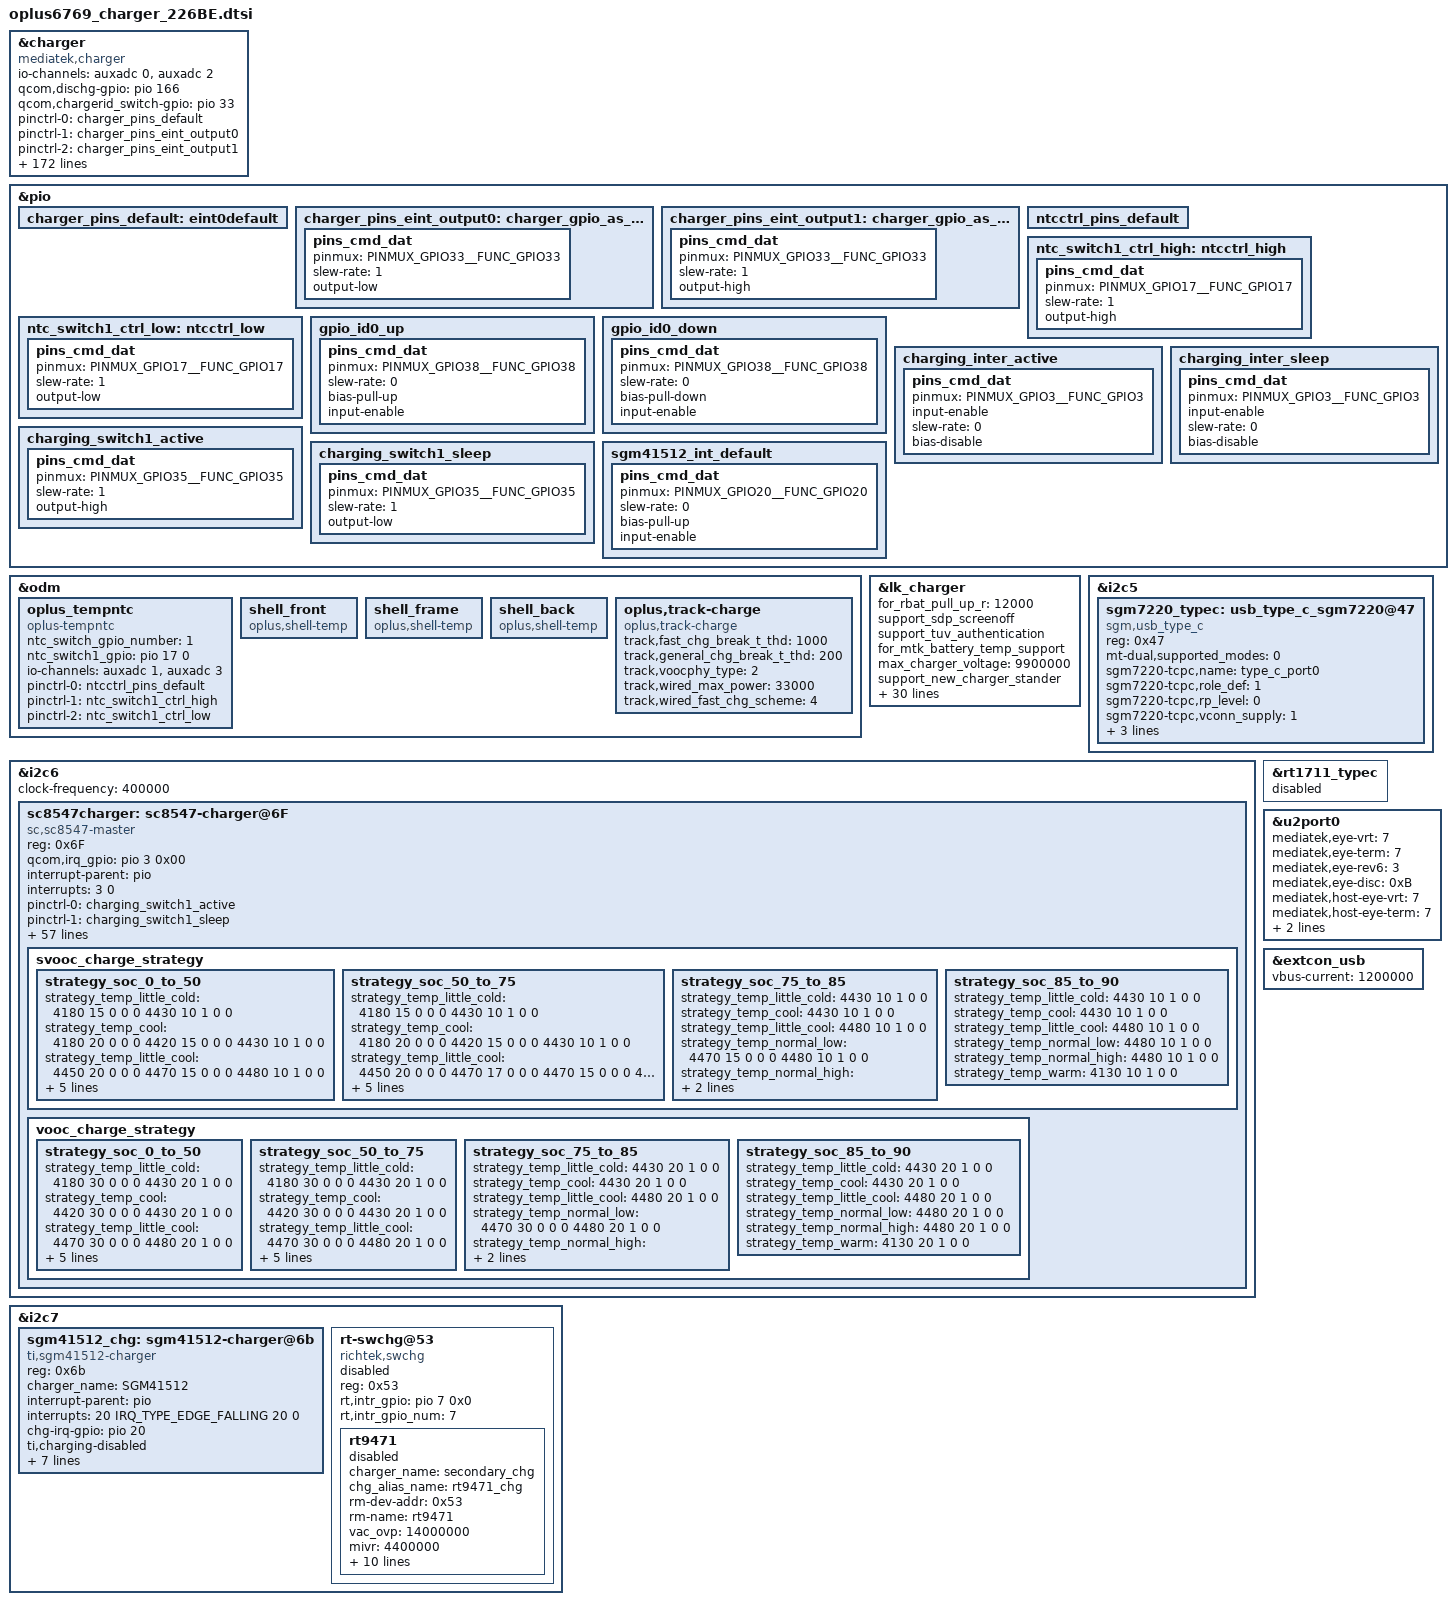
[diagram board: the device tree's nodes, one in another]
// SPDX-License-Identifier: GPL-2.0-only
/*
* Copyright (C) 2020-2021 Oplus. All rights reserved.
*/

//#ifdef OPLUS_CHARGER_BASIC
/*
 * Add for charger bringup
 *
 * CPU:MT6765
 * IRQB
 * CHG_INT(cp irq)                --> GPIO3
 * CC_INTB(cc login irq)          --> GPIO17
 * EINT_CHG_M(main irq)           --> GPIO90
 *
 * GPIO
 * MAIN/CCLOGIN_SCL               --> GPIO48(SCL5)
 * MAIN/CCLOGIN_SDA               --> GPIO49(SDA5)
 * SW_CTRL(uart/vooc switch)      --> GPIO97
 * DISCHARGE_EN(防烧口)           --> GPIO153
 * CHARGER_PUMP_SCL               --> GPIO161(SCL6)
 * CHARGER_PUMP_SDA               --> GPIO162(SDA6)
 * USB_ON(usb/uart&vooc switch)   --> GPIO177
 *
 * AUXADC:
 * 0				-->
 * 1				-->
 * 2				--> USB_TEM_ADC_2
 * 3				-->
 * 4				--> USB_TEM_ADC_1
 * 5				-->
 * 6				-->
 * 7				-->
 * 8				-->
 */
&charger {
	compatible = "mediatek,charger";
	//chgntc_gpio = <&pio 154 0>;

	io-channels = <&auxadc 0>, <&auxadc 2>;
	io-channel-names = "usbtemp-ch3", "usbtemp-ch4";

	qcom,dischg-gpio = <&pio 166 0x00>;
	qcom,chargerid_switch-gpio = <&pio 33 0x00>;
	pinctrl-names = "default", "charger_gpio_as_output_low","charger_gpio_as_output_high", "dischg_disable", "dischg_enable";
	pinctrl-0 = <&charger_pins_default>;
	pinctrl-1 = <&charger_pins_eint_output0>;
	pinctrl-2 = <&charger_pins_eint_output1>;
	pinctrl-3 = <&mtk_pins_usb_burn_en0>;
	pinctrl-4 = <&mtk_pins_usb_burn_en1>;
	//pinctrl-3 = <&ship_sleep_gpio>;
	//pinctrl-4 = <&ship_active_gpio>;
	//pinctrl-5 = <&shortc_active_gpio>;

	chg_battery_id;

	qcom,input_current_charger_ma = <2000>;
	qcom,pd_input_current_charger_ma = <1500>;
	qcom,qc_input_current_charger_ma = <2000>;
	qcom,input_current_usb_ma = <500>;
	qcom,input_current_cdp_ma = <1500>;
	qcom,input_current_camera_ma = <1200>;
	qcom,input_current_calling_ma = <1500>;

	qcom,led_warm_bat_decidegc = <350>;
	qcom,led_high_bat_decidegc = <370>;
	qcom,input_current_led_ma = <1200>;
	qcom,input_current_led_ma_high = <1200>;
	qcom,input_current_led_ma_warm = <1500>;
	qcom,input_current_led_ma_normal = <2000>;

	qcom,vooc_temp_bat_normal_decidegc = <350>;
	qcom,vooc_temp_bat_warm_decidegc = <370>;
	qcom,vooc_temp_bat_hot_decidegc = <440>;
	qcom,input_current_vooc_led_ma_high = <1200>;
	qcom,input_current_vooc_led_ma_warm = <1800>;
	qcom,input_current_vooc_led_ma_normal = <3600>;
	qcom,input_current_vooc_ma_normal = <3600>;

	qcom,input_current_vooc_ma_warm = <3200>;

	qcom,input_current_vooc_ma_high = <2200>;

	qcom,charger_current_vooc_ma_normal = <1800>;

	qcom,iterm_disabled = <0>;
	qcom,iterm_ma = <254>;
	qcom,recharge-mv = <100>;
	qcom,batt_capacity_mah = <5000>;/*typical capacity*/

	qcom,removed_bat_decidegc = <190>;  /*<-19C*/

	qcom,cold_bat_decidegc = <100>;  /*-10C~0C*/
	qcom,temp_cold_vfloat_mv = <4435>;
	qcom,temp_cold_fastchg_current_ma = <600>;
	qcom,temp_cold_fastchg_current_ma_high = <960>;
	qcom,temp_cold_fastchg_current_ma_low = <720>;
	qcom,pd_temp_cold_fastchg_current_ma_high = <800>;
	qcom,pd_temp_cold_fastchg_current_ma_low = <600>;
	qcom,qc_temp_cold_fastchg_current_ma_high = <800>;
	qcom,qc_temp_cold_fastchg_current_ma_low = <600>;

	qcom,little_cold_bat_decidegc = <0>;    /*0C~5C*/
	qcom,temp_little_cold_vfloat_mv = <4435>;
	qcom,temp_little_cold_fastchg_current_ma_high = <2200>;
	qcom,temp_little_cold_fastchg_current_ma_low = <2000>;
	qcom,temp_little_cold_fastchg_current_ma = <2000>;
	qcom,pd_temp_little_cold_fastchg_current_ma_high = <3000>;
	qcom,pd_temp_little_cold_fastchg_current_ma_low = <2000>;
	qcom,qc_temp_little_cold_fastchg_current_ma_high = <3000>;
	qcom,qc_temp_little_cold_fastchg_current_ma_low = <2000>;

	qcom,cool_bat_decidegc = <50>;  /*5C~12C*/
	qcom,temp_cool_vfloat_mv = <4435>;
	qcom,temp_cool_fastchg_current_ma_high = <2200>;
	qcom,temp_cool_fastchg_current_ma_low = <2200>;
	qcom,pd_temp_cool_fastchg_current_ma_high = <3000>;
	qcom,pd_temp_cool_fastchg_current_ma_low = <3000>;
	qcom,qc_temp_cool_fastchg_current_ma_high = <3000>;
	qcom,qc_temp_cool_fastchg_current_ma_low = <3000>;

	qcom,little_cool_bat_decidegc = <120>;  /*12C~16C*/
	qcom,temp_little_cool_vfloat_mv = <4435>;
	qcom,temp_little_cool_fastchg_current_ma = <2200>;
	qcom,pd_temp_little_cool_fastchg_current_ma = <3000>;
	qcom,qc_temp_little_cool_fastchg_current_ma = <3000>;

	qcom,normal_bat_decidegc = <160>;       /*16C~45C*/
	qcom,temp_normal_vfloat_mv = <4435>;
	qcom,temp_normal_fastchg_current_ma = <2200>;
	qcom,pd_temp_normal_fastchg_current_ma = <3000>;
	qcom,qc_temp_normal_fastchg_current_ma = <3000>;

	qcom,warm_bat_decidegc = <450>;         /*45C~53C*/ /*8pin Bat Vooc project need add 3 degree C*/
	qcom,temp_warm_vfloat_mv = <4130>;
	qcom,temp_warm_fastchg_current_ma = <2200>;
	qcom,pd_temp_warm_fastchg_current_ma = <2200>;
	qcom,qc_temp_warm_fastchg_current_ma = <2200>;
	qcom,temp_warm_fastchg_current_ma_led_on = <1000>;

	qcom,hot_bat_decidegc = <530>;

	qcom,non_standard_vfloat_mv = <3980>;
	qcom,non_standard_fastchg_current_ma = <500>;

	qcom,short_c_bat_cv_mv = <4330>;
	qcom,short_c_bat_vfloat_mv = <3800>;
	qcom,short_c_bat_fastchg_current_ma = <512>;

	qcom,cold_vfloat_sw_limit = <4385>;
	qcom,little_cold_vfloat_sw_limit = <4385>;
	qcom,cool_vfloat_sw_limit = <4385>;
	qcom,little_cool_vfloat_sw_limit = <4385>;
	qcom,normal_vfloat_sw_limit = <4385>;
	qcom,warm_vfloat_sw_limit = <4080>;
	qcom,non_standard_vfloat_sw_limit = <3930>;
	qcom,short_c_bat_vfloat_sw_limit = <3750>;

	qcom,max_chg_time_sec = <64800>;
	qcom,charger_hv_thr = <10000>;
	qcom,charger_recv_thr = <9800>;
	qcom,charger_lv_thr = <3400>;
	qcom,vbatt_full_thr = <4435>;
	qcom,vbatt_hv_thr = <4600>;

	qcom,vfloat_step_mv = <8>;
	qcom,cold_vfloat_over_sw_limit = <4445>;
	qcom,little_cold_vfloat_over_sw_limit = <4445>;
	qcom,cool_vfloat_over_sw_limit = <4445>;
	qcom,little_cool_vfloat_over_sw_limit = <4445>;
	qcom,normal_vfloat_over_sw_limit = <4445>;
	qcom,warm_vfloat_over_sw_limit = <4140>;
	qcom,non_standard_vfloat_over_sw_limit = <3990>;

	qcom,vbatt_power_off = <3300>;
	qcom,vbatt_soc_1 = <3410>;
	qcom,vooc_project = <5>;
	qcom,vbatt_num = <1>;
	qcom,voocphy_support = <2>;
	qcom,chargerid_support;
	qcom,ffc_support;
	qcom,smart_charging_screenoff;
	qcom,vooc_show_ui_soc_decimal;
	qcom,ui_soc_decimal_speedmin = <20>;//2A
	qcom,check_batt_full_by_sw;
	qcom,chg_ctrl_by_lcd;
	qcom,chg_ctrl_by_camera;
	qcom,chg_ctrl_by_calling;
	voocphy_support_display_vooc;
	qcom,support_ntc_01c_precision;
	qcom,sw_vfloat_over_protect_enable;

	qcom,normal_vterm_hw_inc = <18>;
	qcom,non_normal_vterm_hw_inc = <18>;
	qcom,usbtemp_batttemp_gap = <12>;

	qcom,ff1_normal_fastchg_ma = <1500>;
	qcom,ff1_warm_fastchg_ma = <1500>;

	qcom,ffc2_normal_fastchg_ma = <1300>;/*12C~35c*/
	qcom,ffc2_temp_warm_decidegc = <350>;
	qcom,ffc2_warm_fastchg_ma = <1400>;/*35C~40c*/
	qcom,ffc2_temp_high_decidegc = <400>;
	qcom,ffc2_temp_low_decidegc = <120>;

	qcom,ff1_exit_step_ma = <450>;
	qcom,ff1_warm_exit_step_ma = <350>;
	qcom,ffc2_exit_step_ma = <150>;
	qcom,ffc2_warm_exit_step_ma = <150>;

	qcom,ffc_normal_vfloat_sw_limit = <4475>;
	qcom,ffc_temp_normal_vfloat_mv = <4550>;
	qcom,ffc_normal_vfloat_over_sw_limit = <4550>;
	qcom,ffc_warm_vfloat_sw_limit = <4475>;

	qcom,ffc2_normal_vfloat_sw_limit = <4475>;
	qcom,ffc2_temp_normal_vfloat_mv = <4550>;
	qcom,ffc2_normal_vfloat_over_sw_limit = <4550>;
	qcom,ffc2_warm_vfloat_sw_limit = <4475>;

	qcom,default_iterm_ma = <254>;
	qcom,default_temp_normal_fastchg_current_ma = <2200>;
	qcom,default_normal_vfloat_sw_limit = <4385>;
	qcom,default_temp_normal_vfloat_mv = <4435>;
	qcom,default_normal_vfloat_over_sw_limit = <4445>;

	qcom,default_temp_little_cool_fastchg_current_ma = <2200>;
	qcom,default_little_cool_vfloat_sw_limit = <4385>;
	qcom,default_temp_little_cool_vfloat_mv = <4435>;
	qcom,default_little_cool_vfloat_over_sw_limit = <4445>;

	//for PD9V or QC9V
	qcom,vbatt_pdqc_to_5v_thr = <4500>;
	qcom,vbatt_pdqc_to_9v_thr = <4500>;

	qcom,vooc-max-input-volt-support = <10000>;     //10V
	qcom,vooc-max-input-current-support = <3000>;   //3A
	qcom,disable-ship-mode;
	qcom,pd_not_support = <1>;
	qcom,qc_not_support = <1>;
	qcom,support_3p6_standard;
	qcom,usb_ntc_pullup = <100000>;
	qcom,mastercharger_psy_set;

	status = "okay";
 };

 &pio {
	charger_pins_default: eint0default {
	};

	charger_pins_eint_output0: charger_gpio_as_output_low {
		pins_cmd_dat {
			pinmux = <PINMUX_GPIO33__FUNC_GPIO33>;
			slew-rate = <1>;
			output-low;
		};
	};

	charger_pins_eint_output1: charger_gpio_as_output_high {
		pins_cmd_dat {
			pinmux = <PINMUX_GPIO33__FUNC_GPIO33>;
			slew-rate = <1>;
			output-high;
		};
	};

	ntcctrl_pins_default: ntcctrl_pins_default {
	};

	ntc_switch1_ctrl_high: ntcctrl_high {
		pins_cmd_dat {
			pinmux = <PINMUX_GPIO17__FUNC_GPIO17>;
			slew-rate = <1>;//0:input direction 1:output direction
			output-high;
		};
	};

	ntc_switch1_ctrl_low: ntcctrl_low {
		pins_cmd_dat {
			pinmux = <PINMUX_GPIO17__FUNC_GPIO17>;
			slew-rate = <1>;
			output-low;
		};
	};
 };

&odm {
	oplus_tempntc: oplus_tempntc {
		compatible = "oplus-tempntc";
		ntc_switch_gpio_number = <1>;
		ntc_switch1_gpio = <&pio 17 0>;
		io-channels = <&auxadc 1>,
				<&auxadc 3>;
		io-channel-names = "auxadc1-flash_or_pa_v",
					"auxadc3-bat_id_or_charge_v";
		pinctrl-names = "default",
			"ntc_switch1_ctrl_high",
			"ntc_switch1_ctrl_low";
		pinctrl-0 = <&ntcctrl_pins_default>;
		pinctrl-1 = <&ntc_switch1_ctrl_high>;
		pinctrl-2 = <&ntc_switch1_ctrl_low>;
		status = "okay";
	};
	shell_front {
 			compatible = "oplus,shell-temp";
 	};

 	shell_frame {
 			compatible = "oplus,shell-temp";
 	};

 	shell_back {
 			compatible = "oplus,shell-temp";
 	};
	oplus,track-charge {
		compatible = "oplus,track-charge";
		track,fast_chg_break_t_thd = <1000>;
		track,general_chg_break_t_thd = <200>;
		track,voocphy_type = <2>;
		track,wired_max_power = <33000>;
		track,wired_fast_chg_scheme = <4>;
	};
};

/* Modify lk charge config */
&lk_charger{
	for_rbat_pull_up_r = <12000>;
	support_sdp_screenoff;
	support_tuv_authentication;
	for_mtk_battery_temp_support;
	max_charger_voltage = <9900000>;
	support_new_charger_stander;
	usb_charger_current = <500000>;
	ac_charger_input_current = <2000000>;
	non_std_ac_charger_current = <2000000>;
	charging_host_charger_current = <1500000>;
	precharge_1_step_current = <350>;

	cold_bat_decidegc = <10>;  /*-10C~0C*/
	dcp_temp_cold_fastchg_current = <300>;
	usb_temp_cold_fastchg_current = <300>;
	cdp_temp_cold_fastchg_current = <300>;

	little_cold_bat_decidegc = <0>;    /*0C~5C*/
	dcp_temp_little_cold_fastchg_current = <800>;
	usb_temp_little_cold_fastchg_current = <500>;
	cdp_temp_little_cold_fastchg_current = <800>;

	cool_bat_decidegc = <5>;  /*5C~12C*/
	dcp_temp_cool_fastchg_current = <1600>;
	usb_temp_cool_fastchg_current = <600>;
	cdp_temp_cool_fastchg_current = <1600>;

	little_cool_bat_decidegc = <12>;  /*12C~16C*/
	dcp_temp_little_cool_fastchg_current = <1600>;
	usb_temp_little_cool_fastchg_current = <600>;
	cdp_temp_little_cool_fastchg_current = <1600>;

	normal_bat_decidegc = <16>;       /*16C~45C*/
	dcp_temp_normal_fastchg_current = <2200>;
	usb_temp_normal_fastchg_current = <600>;
	cdp_temp_normal_fastchg_current = <1600>;

	warm_bat_decidegc = <45>;    /*45C~53C*/
	dcp_temp_warm_fastchg_current = <2200>;
	usb_temp_warm_fastchg_current = <600>;
	cdp_temp_warm_fastchg_current = <2200>;

	hot_bat_decidegc = <53>;
};

&i2c5 {
	sgm7220_typec: usb_type_c_sgm7220@47 {
		compatible = "sgm,usb_type_c"; //
		reg = <0x47>;
		mt-dual,supported_modes = <0>; /* 0: dfp/ufp, 1: dfp, 2: ufp */
		sgm7220-tcpc,name = "type_c_port0"; /* tcpc_device's name */ //

		/* 0: SNK Only, 1: SRC Only, 2: DRP, 3: Try.SRC, 4: Try.SNK */
		sgm7220-tcpc,role_def = <1>;

		sgm7220-tcpc,rp_level = <0>; /* 0: Default, 1: 1.5, 2: 3.0 */ //
		/* 0: Never, 1: Always, 2: EMarkOnly, 3: StartOnly */
		sgm7220-tcpc,vconn_supply  = <1>; //

		/* the number of notifier supply */
		sgm7220-tcpc,notifier_supply_num = <3>; //

		sgm7220,intr_gpio = <&pio 41 0x0>; //
		sgm7220,intr_gpio_num = <41>; //

		// mt6360pd,pcb_gpio = <&pio 5 0x0>;
		// mt6360pd,pcb_gpio_num = <5>;
		// interrupt-parent = <&subpmic_mtk>;
		// interrupts = <64 0>;
		// interrupt-names = "usbid_evt";
		// bootmode = <&chosen>;
        status = "okay";
	};
};

&i2c6 {
	status = "okay";
	clock-frequency = <400000>;//400K
	sc8547charger: sc8547-charger@6F {
		compatible = "sc,sc8547-master";
		reg = <0x6F>;

		//charger_name = "primary_chg";
		qcom,irq_gpio = <&pio 3 0x00>;
		interrupt-parent = <&pio>;
		interrupts = <3 0>;

		pinctrl-names = "switch1_act_switch2_act", "switch1_sleep_switch2_sleep",
				"charging_inter_active", "charging_inter_sleep";
		pinctrl-0 = <&charging_switch1_active>;
		pinctrl-1 = <&charging_switch1_sleep>;
		pinctrl-2 = <&charging_inter_active>;
		pinctrl-3 = <&charging_inter_sleep>;

		qcom,charging_switch1-gpio = <&pio 35 0x00>;

		qcom,voocphy_current_default = <30>;

		qcom,svooc_cool_down_current_limit = <100 20 20 24 30 34 40 44 50 54 60 100>;
		qcom,vooc_cool_down_current_limit = <60 20 20 24 30 34 40 44 50 54 60>;

		qcom,vooc_little_cold_full_voltage = <4430>;
		qcom,vooc_cool_full_voltage = <4430>;
		qcom,vooc_warm_full_voltage = <4130>;
		qcom,vooc_1time_full_voltage = <4480>;
		qcom,vooc_ntime_full_voltage = <4480>;
		qcom,low_curr_full_t1 = <120>;
		qcom,low_curr_full_t2 = <350>;
		qcom,low_curr_full_t3 = <430>;
		qcom,range1_low_curr_full = <1150 4480
						1050 4475
						950 4460
						850 4450
						750 4440>;
		qcom,range2_low_curr_full = <1250 4480
						1150 4475
						1050 4460
						950 4450
						850 4440>;

		qcom,vooc_multistep_initial_batt_temp = <1000>;
		qcom,vooc_little_cool_temp = <160>;
		qcom,vooc_cool_temp = <120>;
		qcom,vooc_little_cold_temp = <50>;
		qcom,vooc_normal_low_temp = <250>;
		qcom,vooc_strategy_normal_current = <100>;
		qcom,vooc_normal_to_little_cool_current = <100>;
		qcom,vooc_batt_over_high_temp = <510>;
		qcom,vooc-low-temp = <0>;
		qcom,vooc-high-temp = <500>;
		qcom,vooc-low-soc = <0>;
		qcom,vooc-high-soc = <90>;
		qcom,vooc-normal-high-temp = <430>;
		qcom,vooc-warm-allow-vol = <4000>;
		qcom,vooc-warm-allow-soc = <50>;

		qcom,vooc_strategy1_batt_high_temp0 = <385>;
		qcom,vooc_strategy1_batt_high_temp1 = <395>;
		qcom,vooc_strategy1_batt_high_temp2 = <420>;
		qcom,vooc_strategy1_batt_low_temp2 = <410>;
		qcom,vooc_strategy1_batt_low_temp1 = <385>;
		qcom,vooc_strategy1_batt_low_temp0 = <375>;

		qcom,vooc_strategy1_high_current0 = <60>;
		qcom,vooc_strategy1_high_current1 = <60>;
		qcom,vooc_strategy1_high_current2 = <40>;
		qcom,vooc_strategy1_low_current2 = <60>;
		qcom,vooc_strategy1_low_current1 = <60>;
		qcom,vooc_strategy1_low_current0 = <100>;

		qcom,voocphy_ibat_over_current = <7500>;
		qcom,voocphy_cp_max_ibus = <3500>;

		qcom,voocphy_freq_mincore = <1800000>;
		qcom,voocphy_freq_midcore = <2000000>;
		qcom,voocphy_freq_maxcore = <2000000>;
		qcom,voocphy_current_change_timeout = <100>;

		svooc_batt_sys_curve = <0 0 1 1 1 1 0	// 3000mA
					0 0 0 0 0 0 1	// 3414mV
					0 0 1 0 1 0 0	// 2000mA
					1 1 1 0 0 1 0	// 4550mV
					0 0 0 1 0 1 0	// 1000mA
					1 1 1 0 0 1 0>;	// 4550mV

		vooc_batt_sys_curve =  <0 0 1 1 1 1 0	// 3000mA
					0 0 0 0 0 0 1	// 3414mV
					0 0 1 0 1 0 0	// 2000mA
					1 1 1 0 0 1 0	// 4550mV
					0 0 0 1 0 1 0	// 1000mA
					1 1 1 0 0 1 0>;	// 4550mV

		svooc_charge_strategy {
			strategy_soc_0_to_50 {
				strategy_temp_little_cold =	<4180 15 0 0 0
								 4430 10 1 0 0>;
				strategy_temp_cool =		<4180 20 0 0 0
								 4420 15 0 0 0
								 4430 10 1 0 0>;
				strategy_temp_little_cool = 	<4450 20 0 0 0
								 4470 15 0 0 0
								 4480 10 1 0 0>;
				strategy_temp_normal_low =	<4200 30 0 1200 0
								 4450 25 0 1200 0
								 4450 23 0 0 0
								 4450 20 0 0 0
								 4470 17 0 0 0
								 4470 15 0 0 0
								 4480 10 1 0 0>;
				strategy_temp_normal_high =	<4200 30 0 1200 0
								 4450 25 0 1200 0
								 4450 23 0 0 0
								 4450 20 0 0 0
								 4470 17 0 0 0
								 4470 15 0 0 0
								 4480 10 1 0 0>;
				strategy_temp_warm =		<4130 10 1 0 0>;
			};

			strategy_soc_50_to_75 {
				strategy_temp_little_cold =	<4180 15 0 0 0
								 4430 10 1 0 0>;
				strategy_temp_cool =		<4180 20 0 0 0
								 4420 15 0 0 0
								 4430 10 1 0 0>;
				strategy_temp_little_cool =	<4450 20 0 0 0
								 4470 17 0 0 0
								 4470 15 0 0 0
								 4480 10 1 0 0>;
				strategy_temp_normal_low =	<4450 25 0 1200 0
								 4450 23 0 0 0
								 4450 20 0 0 0
								 4470 17 0 0 0
								 4470 15 0 0 0
								 4480 10 1 0 0>;
				strategy_temp_normal_high =	<4450 25 0 1200 0
								 4450 23 0 0 0
								 4450 20 0 0 0
								 4470 17 0 0 0
								 4470 15 0 0 0
								 4480 10 1 0 0>;
				strategy_temp_warm =		<4130 10 1 0 0>;
			};

			strategy_soc_75_to_85 {
				strategy_temp_little_cold = 	<4430 10 1 0 0>;
				strategy_temp_cool =		<4430 10 1 0 0>;
				strategy_temp_little_cool =	<4480 10 1 0 0>;
				strategy_temp_normal_low =	<4470 15 0 0 0
								 4480 10 1 0 0>;
				strategy_temp_normal_high =	<4470 15 0 0 0
								 4480 10 1 0 0>;
				strategy_temp_warm =		<4130 10 1 0 0>;
			};

			strategy_soc_85_to_90 {
				strategy_temp_little_cold = 	<4430 10 1 0 0>;
				strategy_temp_cool =		<4430 10 1 0 0>;
				strategy_temp_little_cool =	<4480 10 1 0 0>;
				strategy_temp_normal_low =	<4480 10 1 0 0>;
				strategy_temp_normal_high =	<4480 10 1 0 0>;
				strategy_temp_warm =		<4130 10 1 0 0>;
			};
		};

		vooc_charge_strategy {
			strategy_soc_0_to_50 {
				strategy_temp_little_cold =	<4180 30 0 0 0
								 4430 20 1 0 0>;
				strategy_temp_cool =		<4420 30 0 0 0
								 4430 20 1 0 0>;
				strategy_temp_little_cool =	<4470 30 0 0 0
								 4480 20 1 0 0>;
				strategy_temp_normal_low =	<4470 30 0 0 0
								 4480 20 1 0 0>;
				strategy_temp_normal_high =	<4470 30 0 0 0
								 4480 20 1 0 0>;
				strategy_temp_warm =		<4130 20 1 0 0>;
			};

			strategy_soc_50_to_75 {
				strategy_temp_little_cold =	<4180 30 0 0 0
								 4430 20 1 0 0>;
				strategy_temp_cool =		<4420 30 0 0 0
								 4430 20 1 0 0>;
				strategy_temp_little_cool =	<4470 30 0 0 0
								 4480 20 1 0 0>;
				strategy_temp_normal_low =	<4470 30 0 0 0
								 4480 20 1 0 0>;
				strategy_temp_normal_high =	<4470 30 0 0 0
								 4480 20 1 0 0>;
				strategy_temp_warm =		<4130 20 1 0 0>;
			};

			strategy_soc_75_to_85 {
				strategy_temp_little_cold =	<4430 20 1 0 0>;
				strategy_temp_cool =		<4430 20 1 0 0>;
				strategy_temp_little_cool =	<4480 20 1 0 0>;
				strategy_temp_normal_low =	<4470 30 0 0 0
								 4480 20 1 0 0>;
				strategy_temp_normal_high =	<4470 30 0 0 0
								 4480 20 1 0 0>;
				strategy_temp_warm =		<4130 20 1 0 0>;
			};

			strategy_soc_85_to_90 {
				strategy_temp_little_cold =	<4430 20 1 0 0>;
				strategy_temp_cool =		<4430 20 1 0 0>;
				strategy_temp_little_cool =	<4480 20 1 0 0>;
				strategy_temp_normal_low =	<4480 20 1 0 0>;
				strategy_temp_normal_high =	<4480 20 1 0 0>;
				strategy_temp_warm =		<4130 20 1 0 0>;
			};
		};
	};
};

&i2c7 {
	sgm41512_chg:sgm41512-charger@6b {
                status = "okay";
                compatible = "ti,sgm41512-charger";
                reg = <0x6b>;
                charger_name = "SGM41512";
                interrupt-parent = <&pio>;
                interrupts = <20 IRQ_TYPE_EDGE_FALLING 20 0>;
                chg-irq-gpio = <&pio 20 0x0>;
                ti,charging-disabled;
                ti,sgm41512,enable-term;

                ti,sgm41512,charge-voltage = <4400>;
                ti,sgm41512,charge-current = <3000>;
                ti,sgm41512,input-current-limit = <3000>;
                ti,sgm41512,input-voltage-limit = <4500>;
                ti,sgm41512,vbatlow-volt = <3500>;
                ti,sgm41512,term-current = <1000>;
        };
};

/*the id config to project dts.*/
&pio{
	gpio_id0_up: gpio_id0_up {
		pins_cmd_dat {
			pinmux = <PINMUX_GPIO38__FUNC_GPIO38>;
			slew-rate = <0>;
			bias-pull-up;
			input-enable;
		};
	};
	gpio_id0_down: gpio_id0_down {
		pins_cmd_dat {
			pinmux = <PINMUX_GPIO38__FUNC_GPIO38>;
			slew-rate = <0>;
			bias-pull-down;
			input-enable;
		};
	};
	charging_inter_active: charging_inter_active {
		pins_cmd_dat {
			pinmux = <PINMUX_GPIO3__FUNC_GPIO3>;
			input-enable;
			slew-rate = <0>;
			bias-disable;
		};
	};
	charging_inter_sleep: charging_inter_sleep {
		pins_cmd_dat {
			pinmux = <PINMUX_GPIO3__FUNC_GPIO3>;
			input-enable;
			slew-rate = <0>;
			bias-disable;
		};
	};
	charging_switch1_active: charging_switch1_active {
		pins_cmd_dat {
			pinmux = <PINMUX_GPIO35__FUNC_GPIO35>;
			slew-rate = <1>;
			output-high;
		};
	};

	charging_switch1_sleep: charging_switch1_sleep {
		pins_cmd_dat {
			pinmux = <PINMUX_GPIO35__FUNC_GPIO35>;
			slew-rate = <1>;
			output-low;
		};
	};
	sgm41512_int_default: sgm41512_int_default {
		pins_cmd_dat {
			pinmux = <PINMUX_GPIO20__FUNC_GPIO20>;
			slew-rate = <0>;
			bias-pull-up;
			input-enable;
		};
	};
};

&rt1711_typec {
	status = "disabled";
};

&i2c7 {
	#address-cells = <1>;
	#size-cells = <0>;
	rt-swchg@53 {
		compatible = "richtek,swchg";
		reg = <0x53>;
		//status = "okay";
		status = "disabled";

		rt,intr_gpio = <&pio 7 0x0>; /* GPIO */
		rt,intr_gpio_num = <7>; /* direct defined GPIO num */
		/*
		 * rt,ceb_gpio = <&pio 43 0x0>;
		 * rt,ceb_gpio_num = <43>;
		 */
		rt9471 {
			/*
			 * Charger name
			 * Primary charger: primary_chg
			 * Secondary charger: secondary_chg
			 */
			charger_name = "secondary_chg";
			chg_alias_name = "rt9471_chg";
			rm-dev-addr = /bits/ 8 <0x53>;
			rm-name = "rt9471";
			interrupt-names = "wdt", "chg_mivr", "vbus_gd",
					  "bc12_done", "detach", "vac_ov",
					  "otg_fault", "chg_rdy", "chg_done",
					  "aicc_done", "pe_done", "chg_tout",
					  "rechg", "chg_batov";
			vac_ovp = <14000000>;		/* uV */
			mivr = <4400000>;		/* uV */
			aicr = <500000>;		/* uA */
			cv = <4350000>;			/* uV */
			ichg = <1000000>;		/* uA */
			ieoc = <200000>;		/* uA */
			safe_tmr = <10>;		/* hour */
			wdt = <40>;			/* sec */
			/*
			 * 0: MIVR register
			 * 1: MIVR = VBAT + 200mV
			 * 2: MIVR = VBAT + 250mV
			 * >= 3: MIVR = VBAT + 300mV
			 */
			mivr_track = <0>;
			en_safe_tmr;
			en_te;
			/* en_jeita; */
			/* ceb_invert; */
			/* dis_i2c_tout; */
			en_qon_rst;
			/* auto_aicr; */
			status = "disabled";
		};
	};
};

&u2port0 {
		mediatek,eye-vrt = <7>; /* 0~7 */
		mediatek,eye-term = <7>; /* 0~7 */
		mediatek,eye-rev6 = <3>; /* 0~3 */
		mediatek,eye-disc = <0xB>; /* 0~8 */
		mediatek,host-eye-vrt = <7>; /* 0~7 */
		mediatek,host-eye-term = <7>; /* 0~7 */
		mediatek,host-eye-rev6 = <3>; /* 0~3 */
		mediatek,host-eye-disc = <0xB>; /* 0~8 */
};

&extcon_usb {
	vbus-current = <1200000>;
};
